# PIC16LF1773 register map
Vendor: Microchip
Architecture 16Exxx. Special function registers and configuration words.
Registers are 8-bit, read-write, reset 0x0 unless marked. A register's access mark holds for its fields unless they carry their own. Addresses are absolute, and some are shared; only a register's first bit layout is shown; lines under a group give offsets from that group; [hi:lo] are bit positions; {n}, {i} and the like mark numbered series; 'fields as' and 'values as' point back to an identical list; <NAME> marks a mode.

## Further device data
pins=1: VPP/MCLR_n/ICD_n/IOCE3/RE3; 2: AN0/C1IN0-/C2IN0-/C3IN0-/C4IN0-/C5IN0-/C6IN0-/IOCA0/RA0; 3: OPA1OUT/PRG1IN0/PRG2IN1/OPA2IN1+/OPA2IN1-/AN1/C1IN1-/C2IN1-/C3IN1-/C4IN1-/IOCA1/RA1; 4: DAC1OUT1/DAC1REF0-/DAC2REF0-/DAC3REF0-/DAC4REF0-/DAC5REF0-/DAC7REF0-/VREF-/AN2/C1IN0+/C2IN0+/C3IN0+/C4IN0+/C5IN0+/C6IN0+/IOCA2/RA2; 5: DAC1REF0+/DAC2REF0+/DAC3REF0+/DAC4REF0+/DAC5REF0+/DAC7REF0+/VREF+/AN3/C1IN1+/IOCA3/RA3; 6: DAC4OUT1/OPA1IN0+/IOCA4/RA4; 7: DAC2OUT1/OPA1IN0-/AN4/IOCA5/RA5; 8: VSS; 9: OSC1/CLKIN/IOCA7/RA7; 10: OSC2/CLKOUT/C6IN1+/IOCA6/RA6; 11: SOSCO/DAC5OUT1/IOCC0/RC0; 12: SOSCI/DAC7OUT1/IOCC1/RC1; 13: AN14/C5IN2-/C6IN2-/IOCC2/RC2; 14: AN15/C1IN4-/C2IN4-/C3IN4-/C4IN4-/C5IN4-/C6IN4-/C7IN4-/C8IN4-/SCL/IOCC3/RC3; 15: AN16/C5IN3-/C6IN3-/SDA/IOCC4/RC4; 16: OPA3IN0+/AN17/IOCC5/RC5; 17: OPA3OUT/SLMP3IN0/AN18/C5IN1-/C6IN1-/IOCC6/RC6; 18: OPA3IN0-/AN19/IOCC7/RC7; 19: VSS; 20: VDD; 21: AN12/ZCD/C2IN1+/IOCB0/HIB0/RB0; 22: OPA2OUT/PRG1IN1/OPA1IN1+/OPA1IN1-/PRG2IN0/AN10/C1IN3-/C2IN3-/C3IN3-/C4IN3-/IOCB1/HIB1/RB1; 23: DAC3OUT1/OPA2IN0-/AN8/IOCB2/RB2; 24: OPA2IN0+/AN9/C1IN2-/C2IN2-/C3IN2-/IOCB3/RB3; 25: AN11/C3IN1+/IOCB4/RB4; 26: DAC5REF1-/DAC7REF1-/AN13/C4IN2-/IOCB5/RB5; 27: ICSPCLK/ICDCLK/DAC5REF1+/DAC7REF1+/C4IN1+/IOCB6/RB6; 28: ICSPDAT/ICDDAT/DAC1OUT2/DAC2OUT2/DAC5OUT2/DAC3OUT2/DAC4OUT2/DAC7OUT2/C5IN1+/IOCB7/RB7

## DOS_TIMER1_tmr
0x18 TMR1L reset not defined — (power-on value xxxxxxxx)
  [7:0] TMR
0x19 TMR1H reset not defined — (power-on value xxxxxxxx)
  [7:0] TMR
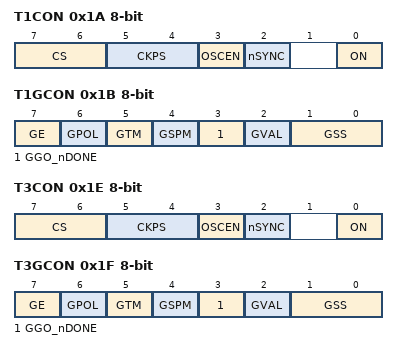
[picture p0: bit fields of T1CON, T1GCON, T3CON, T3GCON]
0x1A T1CON
  [7:6] CS, [5:4] CKPS, [3] OSCEN, [2] nSYNC, [0] ON
0x1B T1GCON reset not defined — (power-on value 00000x00)
  [7] GE, [6] GPOL, [5] GTM, [4] GSPM, [3] GGO_nDONE, [2] GVAL ro, [1:0] GSS
0x1C TMR3L reset not defined — (power-on value xxxxxxxx)
  [7:0] TMR
0x1D TMR3H reset not defined — (power-on value xxxxxxxx)
  [7:0] TMR
0x1E T3CON
  [7:6] CS, [5:4] CKPS, [3] OSCEN, [2] nSYNC, [0] ON
0x1F T3GCON reset not defined — (power-on value 00000x00)
  fields as T1GCON
0x40F TMR5L reset not defined — (power-on value xxxxxxxx)
  [7:0] TMR
0x410 TMR5H reset not defined — (power-on value xxxxxxxx)
  [7:0] TMR
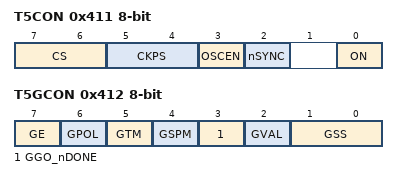
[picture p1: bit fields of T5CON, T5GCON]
0x411 T5CON
  [7:6] CS, [5:4] CKPS, [3] OSCEN, [2] nSYNC, [0] ON
0x412 T5GCON reset not defined — (power-on value 00000x00)
  fields as T1GCON

## cmp_zxover_ctrl
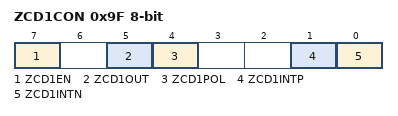
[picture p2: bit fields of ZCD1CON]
0x9F ZCD1CON reset not defined — (power-on value 0-x0--00)
  [7] ZCD1EN, [5] ZCD1OUT ro, [4] ZCD1POL, [1] ZCD1INTP, [0] ZCD1INTN

## cmp_rr
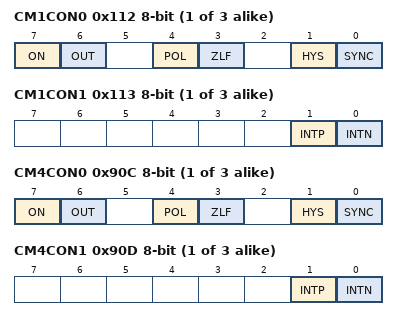
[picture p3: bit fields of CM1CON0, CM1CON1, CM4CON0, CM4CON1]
{0x10E+4i} CM{i}CON0 (i=1..3)
  [7] ON, [6] OUT ro, [4] POL, [3] ZLF, [1] HYS, [0] SYNC
{0x10F+4i} CM{i}CON1 (i=1..3)
  [1] INTP, [0] INTN
{0x110+4i} CM{i}NSEL (i=1..3)
  [3:0] NCH
{0x111+4i} CM{i}PSEL (i=1..3)
  [3:0] PCH
{0x8FC+4i} CM{i}CON0 (i=4..6)
  [7] ON, [6] OUT ro, [4] POL, [3] ZLF, [1] HYS, [0] SYNC
{0x8FD+4i} CM{i}CON1 (i=4..6)
  [1] INTP, [0] INTN
{0x8FE+4i} CM{i}NSEL (i=4..6)
  [3:0] NCH
{0x8FF+4i} CM{i}PSEL (i=4..6)
  [3:0] PCH

## mssp
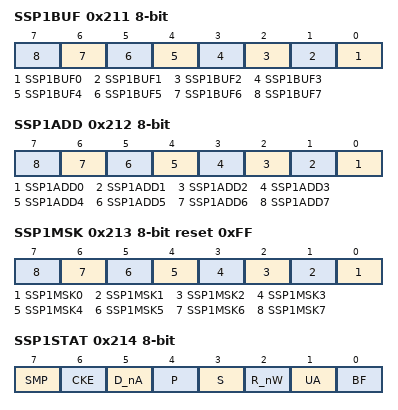
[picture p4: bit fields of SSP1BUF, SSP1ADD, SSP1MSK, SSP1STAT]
0x211 SSP1BUF reset not defined — (power-on value xxxxxxxx)
  [n] SSP1BUF{n} (n=0..7)
0x212 SSP1ADD
  [n] SSP1ADD{n} (n=0..7)
0x213 SSP1MSK reset 0xFF
  [n] SSP1MSK{n} (n=0..7)
0x214 SSP1STAT
  [7] SMP, [6] CKE, [5] D_nA ro, [4] P ro, [3] S ro, [2] R_nW ro, [1] UA ro, [0] BF ro
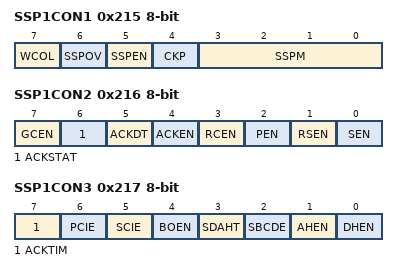
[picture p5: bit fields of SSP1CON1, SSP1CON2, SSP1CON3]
0x215 SSP1CON1
  [7] WCOL, [6] SSPOV, [5] SSPEN, [4] CKP, [3:0] SSPM
0x216 SSP1CON2
  [7] GCEN, [6] ACKSTAT ro, [5] ACKDT, [4] ACKEN, [3] RCEN, [2] PEN, [1] RSEN, [0] SEN
0x217 SSP1CON3
  [7] ACKTIM ro, [6] PCIE, [5] SCIE, [4] BOEN, [3] SDAHT, [2] SBCDE, [1] AHEN, [0] DHEN
